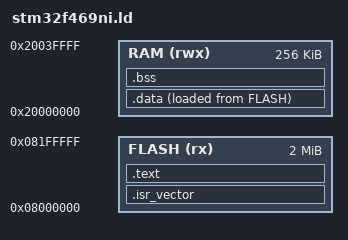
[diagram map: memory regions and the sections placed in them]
/* Linker script cho STM32F469NI */
ENTRY(Reset_Handler)

_estack = 0x20000000 + 256K; /* 256 KB RAM an toàn lúc reset */

MEMORY
{
  FLASH (rx)  : ORIGIN = 0x08000000, LENGTH = 2048K
  RAM   (rwx) : ORIGIN = 0x20000000, LENGTH = 256K
}

SECTIONS
{
  .isr_vector :
  {
    . = ALIGN(4);
    KEEP(*(.isr_vector))
    . = ALIGN(4);
  } >FLASH

  .text :
  {
    . = ALIGN(4);
    *(.text)
    *(.text*)
    *(.rodata)
    *(.rodata*)
    . = ALIGN(4);
    _etext = .;
  } >FLASH

  _sidata = LOADADDR(.data);

  .data :
  {
    . = ALIGN(4);
    _sdata = .;
    *(.data)
    *(.data*)
    . = ALIGN(4);
    _edata = .;
  } >RAM AT> FLASH

  .bss :
  {
    . = ALIGN(4);
    _sbss = .;
    __bss_start__ = _sbss;
    *(.bss)
    *(.bss*)
    *(COMMON)
    . = ALIGN(4);
    _ebss = .;
    __bss_end__ = _ebss;
  } >RAM
}
